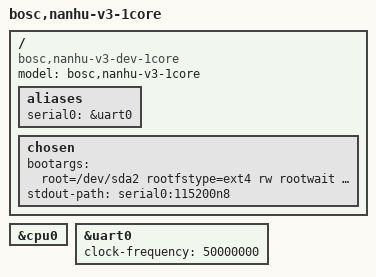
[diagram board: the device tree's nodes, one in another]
// SPDX-License-Identifier: (GPL-2.0 OR MIT)
/* Copyright (c) 2023-2024 BOSC */

/dts-v1/;

#include "nanhu-v3.dtsi"

/ {
	#address-cells = <2>;
	#size-cells = <2>;
	compatible = "bosc,nanhu-v3-dev-1core", "bosc,nanhu-v3";
	model = "bosc,nanhu-v3-1core";

	aliases {
		serial0 = &uart0;
	};

	chosen {
		bootargs = "root=/dev/sda2 rootfstype=ext4 rw rootwait console=ttyS0 earlycon noinitrd";
		stdout-path = "serial0:115200n8";
	};
};

&cpu0 {
	status = "okay";
};

&uart0 {
	clock-frequency = <50000000>;
};
